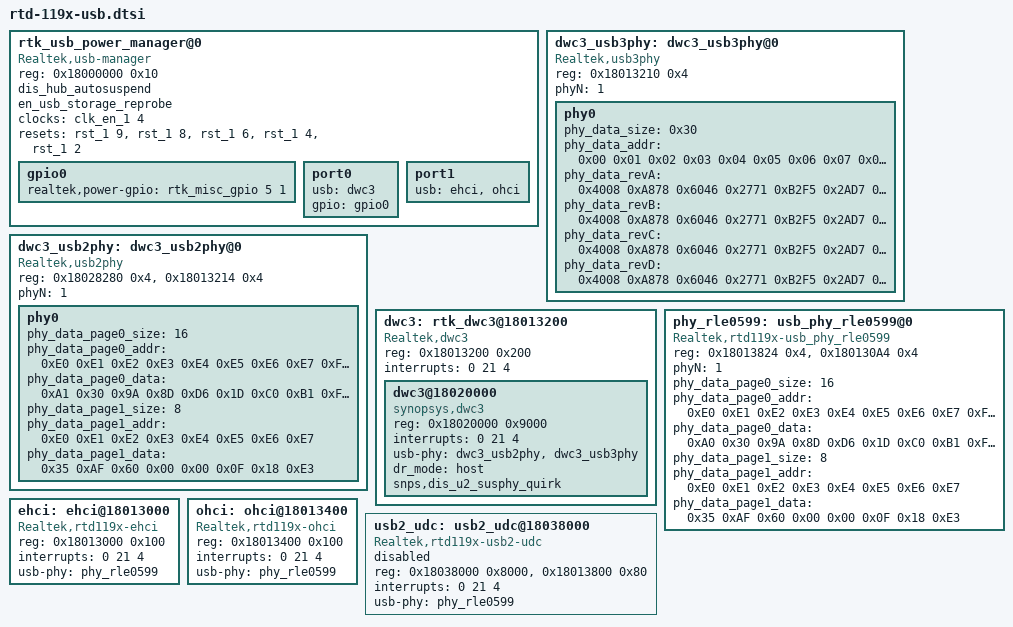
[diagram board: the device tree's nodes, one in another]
/*
 * realtek,port0-power-gpio: port 0 power, output, default low
 * realtek,port1-power-gpio: port 1 power, output, default low
 * realtek,port2-power-gpio: port 2  power, output, default low
 * realtek,port3-power-gpio: 1296 port 3 power, output, default low
 *
 * usb_iso_mode: ISO mode is only port suspend (Default disable)
 * usb_power_cut: Non ISO mode and power cut (Default disable power cut)
 * Note if enable ISO mode, then power_cut will not effective
 */

rtk_usb_power_manager@0 {
	compatible = "Realtek,usb-manager";
	reg = <0x18000000 0x10>;

	dis_hub_autosuspend;
	en_usb_storage_reprobe; /* To enable usb storage re-probe*/
	//rescue_usb; /* For rescue dtb use */

	clocks = <&clk_en_1 4>; /* clk_en_usb */
	clock-names = "clk_en_usb"; /*clk_en_usb*/

	resets = <&rst_1 9>,
		<&rst_1 8>,
		<&rst_1 6>,
		<&rst_1 4>,
		<&rst_1 2>;
	reset-names = "u2phy1",
		"u2phy0",
		"usb",
		"u3phy0",
		"u3mdio0";

	gpio0: gpio0 {
		realtek,power-gpio = <&rtk_misc_gpio 5 1 0>; /*usb3 power , output, default low */
	};

	port0 {
		usb = <&dwc3>;
		gpio = <&gpio0>;
	};
	port1 {
		usb = <&ehci &ohci>;
		//gpio = <&gpio1>;
	};

	//rtk_usb {
	//};
};

dwc3_usb3phy: dwc3_usb3phy@0 {
	compatible = "Realtek,usb3phy";
	reg = <0x18013210 0x4>;
	#address-cells = <1>;
	#size-cells = <1>;
	ranges;
	phyN = <1>;
	phy0 {
		phy_data_size = <0x30>;
		phy_data_addr = /bits/ 8
			<0x00 0x01 0x02 0x03 0x04 0x05 0x06 0x07 0x08 0x09
			0x0A 0x0B 0x0C 0x0D 0x0E 0x0F 0x10 0x11 0x12 0x13
			0x14 0x15 0x16 0x17 0x18 0x19 0x1A 0x1B 0x1C 0x1D
			0x1E 0x1F 0x20 0x21 0x22 0x23 0x24 0x25 0x26 0x27
			0x28 0x29 0x2A 0x2B 0x2C 0x2D 0x2E 0x2F>;
		phy_data_revA = /bits/ 16
			<0x4008 0xA878 0x6046 0x2771 0xB2F5 0x2AD7 0x0001 0x3200 0x3590 0x325C
			 0xD643 0xE909 0xC008 0xFF28 0x2010 0x8000 0x000C 0x4C00 0xFC00 0x0C81
			 0xDE01 0x0000 0x0000 0x0000 0x0000 0x7004 0x1260 0xFF0C 0xCB1C 0xA03F
			 0xC200 0x9000 0xD4FF 0xAAFF 0x0051 0xDB60 0x0800 0x0000 0x0004 0x01D6
			 0xF882 0x3080 0x3083 0x2038 0xFFFF 0xFFFF 0x0000 0x0040>;
		phy_data_revB = /bits/ 16
			<0x4008 0xA878 0x6046 0x2771 0xB2F5 0x2AD7 0x0001 0x3200 0x3592 0x325C
			 0xD643 0xA909 0xC008 0xFF28 0x2010 0x8000 0x000C 0x4C00 0xFC00 0x0C81
			 0xDE01 0x0000 0x0000 0x0000 0x0000 0x3804 0x1260 0xFF0C 0xCB1C 0xA03F
			 0xC200 0x9000 0xD4FF 0xAAFF 0x0051 0xDB60 0x0800 0x0000 0x0004 0x01D6
			 0xF840 0x3080 0x3083 0x2038 0xFFFF 0xFFFF 0x0000 0x0040>;
		phy_data_revC = /bits/ 16
			<0x4008 0xA878 0x6046 0x2771 0xB2F5 0x2AD7 0x0001 0x3200 0x3592 0x325C
			 0xD643 0xA909 0xC008 0xFF28 0x2010 0x8000 0x000C 0x4C00 0xFC00 0x0C81
			 0xDE01 0x0000 0x0000 0x0000 0x0000 0x3804 0x1260 0xFF0C 0xCB1C 0xA03F
			 0xC200 0x9000 0x94FF 0xAAFF 0x0051 0xDB60 0x0800 0x0000 0x0004 0x01D6
			 0xF840 0x3080 0x3083 0x2038 0xFFFF 0xFFFF 0x0000 0x0040>;
		phy_data_revD = /bits/ 16
			<0x4008 0xA878 0x6046 0x2771 0xB2F5 0x2AD7 0x0001 0x3200 0x3592 0x325C
			 0xD643 0xA909 0xC008 0xFF28 0x2010 0x8000 0x000C 0x4C00 0xFC00 0x0C81
			 0xDE01 0x0000 0x0000 0x0000 0x0000 0x3804 0x1260 0xFF0C 0xCB1C 0xA03F
			 0xC200 0x9000 0x94FF 0xAAFF 0x0051 0xDB60 0x0800 0x0000 0x0004 0x01D6
			 0xF840 0x3080 0x3083 0x2038 0xFFFF 0xFFFF 0x0000 0x0040>;
		//do_toggle;
	};
};

dwc3_usb2phy: dwc3_usb2phy@0 {
	compatible = "Realtek,usb2phy";
	reg = <0x18028280 0x4>, <0x18013214 0x4>;
	#address-cells = <1>;
	#size-cells = <1>;
	ranges;
	phyN = <1>;
	phy0 {
		phy_data_page0_size = <16>;
		phy_data_page0_addr = /bits/ 8
			<0xE0 0xE1 0xE2 0xE3 0xE4 0xE5 0xE6 0xE7 0xF0 0xF1
			0xF2 0xF3 0xF4 0xF5 0xF6 0xF7>;
		phy_data_page0_data = /bits/ 8
			<0xA1 0x30 0x9A 0x8D 0xD6 0x1D 0xC0 0xB1 0xFC 0x9C
			0x00 0x11 0x9B 0x81 0x00 0x02>;
		phy_data_page1_size = <8>;
		phy_data_page1_addr = /bits/ 8
			<0xE0 0xE1 0xE2 0xE3 0xE4 0xE5 0xE6 0xE7>;
		phy_data_page1_data = /bits/ 8
			<0x35 0xAF 0x60 0x00 0x00 0x0F 0x18 0xE3>;
		//do_toggle;
		//check_efuse;
	};
};

dwc3: rtk_dwc3@18013200 {
	compatible = "Realtek,dwc3";
	reg = <0x18013200 0x200>;
	interrupts = <0 21 4>;
	#address-cells = <1>;
	#size-cells = <1>;
	ranges;
	//delay_probe_work; //To delay probe work
	//ordered_probe; // ordered probe in delay work

	dwc3@18020000 {
		compatible = "synopsys,dwc3";
		reg = <0x18020000 0x9000>;
		interrupts = <0 21 4>;
		usb-phy = <&dwc3_usb2phy &dwc3_usb3phy>;
		dr_mode = "host";		/* peripheral */
		//tx-fifo-resize;
		snps,dis_u2_susphy_quirk;
	};
};

phy_rle0599: usb_phy_rle0599@0 {
	compatible = "Realtek,rtd119x-usb_phy_rle0599";
	reg = <0x18013824 0x4>, <0x180130A4 0x4>;
	//Note reg addr: REG_WRAP_VStatusOut2, REG_EHCI_INSNREG05
	phyN = <1>;
	phy_data_page0_size = <16>;
	phy_data_page0_addr = /bits/ 8
		<0xE0 0xE1 0xE2 0xE3 0xE4 0xE5 0xE6 0xE7 0xF0 0xF1
		0xF2 0xF3 0xF4 0xF5 0xF6 0xF7>;
	phy_data_page0_data = /bits/ 8
		<0xA0 0x30 0x9A 0x8D 0xD6 0x1D 0xC0 0xB1 0xFC 0x9C
		0x00 0x11 0x9B 0x81 0x00 0x02>;
	phy_data_page1_size = <8>;
	phy_data_page1_addr = /bits/ 8
		<0xE0 0xE1 0xE2 0xE3 0xE4 0xE5 0xE6 0xE7>;
	phy_data_page1_data = /bits/ 8
		<0x35 0xAF 0x60 0x00 0x00 0x0F 0x18 0xE3>;
	//check_efuse;
};

ehci: ehci@18013000 {
	compatible = "Realtek,rtd119x-ehci";
	reg = <0x18013000 0x100>;
	interrupts = <0 21 4>;
	usb-phy = <&phy_rle0599>;
	//delay_probe_work; //To delay probe work
	//ordered_probe; // ordered probe in delay work
	//fixed_async_list_addr_bug; // add to fixed async_list_addr bug
};

ohci: ohci@18013400 {
	compatible = "Realtek,rtd119x-ohci";
	reg = <0x18013400 0x100>;
	interrupts = <0 21 4>;
	usb-phy = <&phy_rle0599>;
	//delay_probe_work; //To delay probe work
	//ordered_probe; // ordered probe in delay work

	//wrap_reg = <0x18013820>;
};

usb2_udc: usb2_udc@18038000 {
	compatible = "Realtek,rtd119x-usb2-udc";
	reg = <0x18038000 0x8000>, <0x18013800 0x80>;
	interrupts = <0 21 4>;
	usb-phy = <&phy_rle0599>;

	status = "disable";
};


